AUTOSAR XML (schema 4-0-3)
package /ComponentType
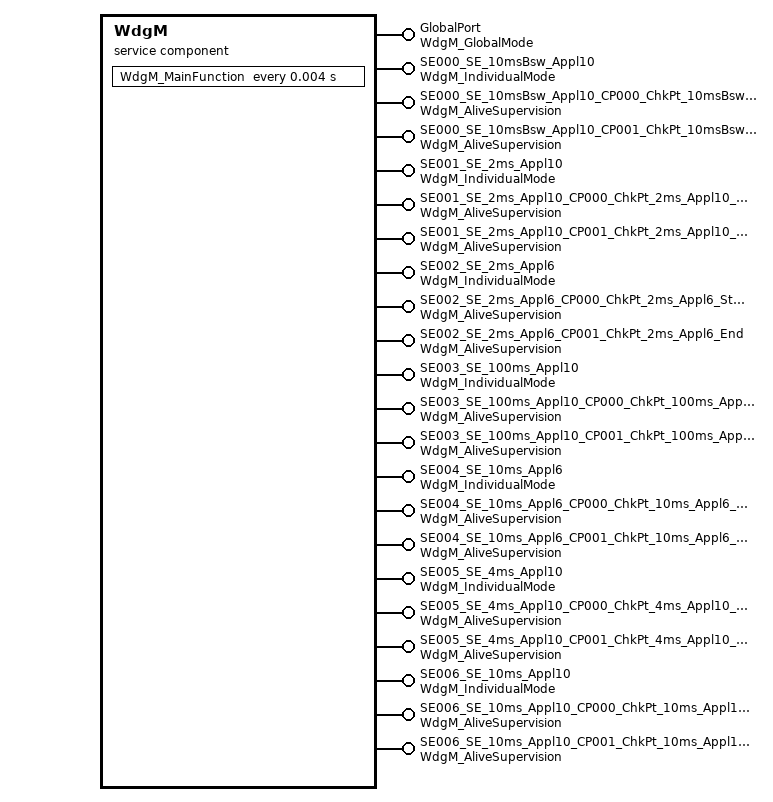
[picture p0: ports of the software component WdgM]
  service sw component type WdgM
    22 x provide port:
      GlobalPort: provided-interface=WdgM_GlobalMode  # P-Port Prototype for Global Mode
        provided-com-specs:
          operation=GetGlobalStatus, queue-length=1
          operation=GetMode, queue-length=1
          operation=PerformReset, queue-length=1
      SE000_SE_10msBsw_Appl10: provided-interface=WdgM_IndividualMode  # P-Port Prototype for Supervised Entity SE_10msBsw_Appl10 with ID 0
        provided-com-specs:
          operation=ActivateSupervisionEntity, queue-length=1
          operation=DeactivateSupervisionEntity, queue-length=1
          operation=GetLocalStatus, queue-length=1
      SE000_SE_10msBsw_Appl10_CP000_ChkPt_10msBsw_Appl10_Strt: server-com-spec{operation=CheckpointReached, queue-length=1}, provided-interface=WdgM_AliveSupervision  # P-Port Prototype for Supervised Entity SE_10msBsw_Appl10 with ID 0 and Checkpoint ChkPt_10msBsw_Appl10_Strt with ID 0.
      SE000_SE_10msBsw_Appl10_CP001_ChkPt_10msBsw_Appl10_End: server-com-spec{operation=CheckpointReached, queue-length=1}, provided-interface=WdgM_AliveSupervision  # P-Port Prototype for Supervised Entity SE_10msBsw_Appl10 with ID 0 and Checkpoint ChkPt_10msBsw_Appl10_End with ID 1.
      SE001_SE_2ms_Appl10: provided-interface=WdgM_IndividualMode  # P-Port Prototype for Supervised Entity SE_2ms_Appl10 with ID 1
        provided-com-specs:
          operation=ActivateSupervisionEntity, queue-length=1
          operation=DeactivateSupervisionEntity, queue-length=1
          operation=GetLocalStatus, queue-length=1
      SE001_SE_2ms_Appl10_CP000_ChkPt_2ms_Appl10_Strt: server-com-spec{operation=CheckpointReached, queue-length=1}, provided-interface=WdgM_AliveSupervision  # P-Port Prototype for Supervised Entity SE_2ms_Appl10 with ID 1 and Checkpoint ChkPt_2ms_Appl10_Strt with ID 0.
      SE001_SE_2ms_Appl10_CP001_ChkPt_2ms_Appl10_End: server-com-spec{operation=CheckpointReached, queue-length=1}, provided-interface=WdgM_AliveSupervision  # P-Port Prototype for Supervised Entity SE_2ms_Appl10 with ID 1 and Checkpoint ChkPt_2ms_Appl10_End with ID 1.
      SE002_SE_2ms_Appl6: provided-interface=WdgM_IndividualMode  # P-Port Prototype for Supervised Entity SE_2ms_Appl6 with ID 2
        provided-com-specs:
          operation=ActivateSupervisionEntity, queue-length=1
          operation=DeactivateSupervisionEntity, queue-length=1
          operation=GetLocalStatus, queue-length=1
      SE002_SE_2ms_Appl6_CP000_ChkPt_2ms_Appl6_Strt: server-com-spec{operation=CheckpointReached, queue-length=1}, provided-interface=WdgM_AliveSupervision  # P-Port Prototype for Supervised Entity SE_2ms_Appl6 with ID 2 and Checkpoint ChkPt_2ms_Appl6_Strt with ID 0.
      SE002_SE_2ms_Appl6_CP001_ChkPt_2ms_Appl6_End: server-com-spec{operation=CheckpointReached, queue-length=1}, provided-interface=WdgM_AliveSupervision  # P-Port Prototype for Supervised Entity SE_2ms_Appl6 with ID 2 and Checkpoint ChkPt_2ms_Appl6_End with ID 1.
      SE003_SE_100ms_Appl10: provided-interface=WdgM_IndividualMode  # P-Port Prototype for Supervised Entity SE_100ms_Appl10 with ID 3
        provided-com-specs:
          operation=ActivateSupervisionEntity, queue-length=1
          operation=DeactivateSupervisionEntity, queue-length=1
          operation=GetLocalStatus, queue-length=1
      SE003_SE_100ms_Appl10_CP000_ChkPt_100ms_Appl10_Strt: server-com-spec{operation=CheckpointReached, queue-length=1}, provided-interface=WdgM_AliveSupervision  # P-Port Prototype for Supervised Entity SE_100ms_Appl10 with ID 3 and Checkpoint ChkPt_100ms_Appl10_Strt with ID 0.
      SE003_SE_100ms_Appl10_CP001_ChkPt_100ms_Appl10_End: server-com-spec{operation=CheckpointReached, queue-length=1}, provided-interface=WdgM_AliveSupervision  # P-Port Prototype for Supervised Entity SE_100ms_Appl10 with ID 3 and Checkpoint ChkPt_100ms_Appl10_End with ID 1.
      SE004_SE_10ms_Appl6: provided-interface=WdgM_IndividualMode  # P-Port Prototype for Supervised Entity SE_10ms_Appl6 with ID 4
        provided-com-specs:
          operation=ActivateSupervisionEntity, queue-length=1
          operation=DeactivateSupervisionEntity, queue-length=1
          operation=GetLocalStatus, queue-length=1
      SE004_SE_10ms_Appl6_CP000_ChkPt_10ms_Appl6_Strt: server-com-spec{operation=CheckpointReached, queue-length=1}, provided-interface=WdgM_AliveSupervision  # P-Port Prototype for Supervised Entity SE_10ms_Appl6 with ID 4 and Checkpoint ChkPt_10ms_Appl6_Strt with ID 0.
      SE004_SE_10ms_Appl6_CP001_ChkPt_10ms_Appl6_End: server-com-spec{operation=CheckpointReached, queue-length=1}, provided-interface=WdgM_AliveSupervision  # P-Port Prototype for Supervised Entity SE_10ms_Appl6 with ID 4 and Checkpoint ChkPt_10ms_Appl6_End with ID 1.
      SE005_SE_4ms_Appl10: provided-interface=WdgM_IndividualMode  # P-Port Prototype for Supervised Entity SE_4ms_Appl10 with ID 5
        provided-com-specs:
          operation=ActivateSupervisionEntity, queue-length=1
          operation=DeactivateSupervisionEntity, queue-length=1
          operation=GetLocalStatus, queue-length=1
      SE005_SE_4ms_Appl10_CP000_ChkPt_4ms_Appl10_Strt: server-com-spec{operation=CheckpointReached, queue-length=1}, provided-interface=WdgM_AliveSupervision  # P-Port Prototype for Supervised Entity SE_4ms_Appl10 with ID 5 and Checkpoint ChkPt_4ms_Appl10_Strt with ID 0.
      SE005_SE_4ms_Appl10_CP001_ChkPt_4ms_Appl10_End: server-com-spec{operation=CheckpointReached, queue-length=1}, provided-interface=WdgM_AliveSupervision  # P-Port Prototype for Supervised Entity SE_4ms_Appl10 with ID 5 and Checkpoint ChkPt_4ms_Appl10_End with ID 1.
      SE006_SE_10ms_Appl10: provided-interface=WdgM_IndividualMode  # P-Port Prototype for Supervised Entity SE_10ms_Appl10 with ID 6
        provided-com-specs:
          operation=ActivateSupervisionEntity, queue-length=1
          operation=DeactivateSupervisionEntity, queue-length=1
          operation=GetLocalStatus, queue-length=1
      SE006_SE_10ms_Appl10_CP000_ChkPt_10ms_Appl10_Strt: server-com-spec{operation=CheckpointReached, queue-length=1}, provided-interface=WdgM_AliveSupervision  # P-Port Prototype for Supervised Entity SE_10ms_Appl10 with ID 6 and Checkpoint ChkPt_10ms_Appl10_Strt with ID 0.
      SE006_SE_10ms_Appl10_CP001_ChkPt_10ms_Appl10_End: server-com-spec{operation=CheckpointReached, queue-length=1}, provided-interface=WdgM_AliveSupervision  # P-Port Prototype for Supervised Entity SE_10ms_Appl10 with ID 6 and Checkpoint ChkPt_10ms_Appl10_End with ID 1.
    behavior WdgM_InternalBehavior
      38 x operation invoked event:
        V_WDGM_SE000_SE_10msBsw_Appl10_ASE: start-on-event=ActivateSupervisionEntity, operation=SE000_SE_10msBsw_Appl10.ActivateSupervisionEntity
        V_WDGM_SE001_SE_2ms_Appl10_ASE: start-on-event=ActivateSupervisionEntity, operation=SE001_SE_2ms_Appl10.ActivateSupervisionEntity
        V_WDGM_SE002_SE_2ms_Appl6_ASE: start-on-event=ActivateSupervisionEntity, operation=SE002_SE_2ms_Appl6.ActivateSupervisionEntity
        V_WDGM_SE003_SE_100ms_Appl10_ASE: start-on-event=ActivateSupervisionEntity, operation=SE003_SE_100ms_Appl10.ActivateSupervisionEntity
        V_WDGM_SE004_SE_10ms_Appl6_ASE: start-on-event=ActivateSupervisionEntity, operation=SE004_SE_10ms_Appl6.ActivateSupervisionEntity
        V_WDGM_SE005_SE_4ms_Appl10_ASE: start-on-event=ActivateSupervisionEntity, operation=SE005_SE_4ms_Appl10.ActivateSupervisionEntity
        V_WDGM_SE006_SE_10ms_Appl10_ASE: start-on-event=ActivateSupervisionEntity, operation=SE006_SE_10ms_Appl10.ActivateSupervisionEntity
        V_WDGM_SE000_SE_10msBsw_Appl10_CP000_ChkPt_10msBsw_Appl10_Strt_CPR: start-on-event=CheckpointReached, operation=SE000_SE_10msBsw_Appl10_CP000_ChkPt_10msBsw_Appl10_Strt.CheckpointReached
        V_WDGM_SE000_SE_10msBsw_Appl10_CP001_ChkPt_10msBsw_Appl10_End_CPR: start-on-event=CheckpointReached, operation=SE000_SE_10msBsw_Appl10_CP001_ChkPt_10msBsw_Appl10_End.CheckpointReached
        V_WDGM_SE001_SE_2ms_Appl10_CP000_ChkPt_2ms_Appl10_Strt_CPR: start-on-event=CheckpointReached, operation=SE001_SE_2ms_Appl10_CP000_ChkPt_2ms_Appl10_Strt.CheckpointReached
        V_WDGM_SE001_SE_2ms_Appl10_CP001_ChkPt_2ms_Appl10_End_CPR: start-on-event=CheckpointReached, operation=SE001_SE_2ms_Appl10_CP001_ChkPt_2ms_Appl10_End.CheckpointReached
        V_WDGM_SE002_SE_2ms_Appl6_CP000_ChkPt_2ms_Appl6_Strt_CPR: start-on-event=CheckpointReached, operation=SE002_SE_2ms_Appl6_CP000_ChkPt_2ms_Appl6_Strt.CheckpointReached
        V_WDGM_SE002_SE_2ms_Appl6_CP001_ChkPt_2ms_Appl6_End_CPR: start-on-event=CheckpointReached, operation=SE002_SE_2ms_Appl6_CP001_ChkPt_2ms_Appl6_End.CheckpointReached
        V_WDGM_SE003_SE_100ms_Appl10_CP000_ChkPt_100ms_Appl10_Strt_CPR: start-on-event=CheckpointReached, operation=SE003_SE_100ms_Appl10_CP000_ChkPt_100ms_Appl10_Strt.CheckpointReached
        V_WDGM_SE003_SE_100ms_Appl10_CP001_ChkPt_100ms_Appl10_End_CPR: start-on-event=CheckpointReached, operation=SE003_SE_100ms_Appl10_CP001_ChkPt_100ms_Appl10_End.CheckpointReached
        V_WDGM_SE004_SE_10ms_Appl6_CP000_ChkPt_10ms_Appl6_Strt_CPR: start-on-event=CheckpointReached, operation=SE004_SE_10ms_Appl6_CP000_ChkPt_10ms_Appl6_Strt.CheckpointReached
        V_WDGM_SE004_SE_10ms_Appl6_CP001_ChkPt_10ms_Appl6_End_CPR: start-on-event=CheckpointReached, operation=SE004_SE_10ms_Appl6_CP001_ChkPt_10ms_Appl6_End.CheckpointReached
        V_WDGM_SE005_SE_4ms_Appl10_CP000_ChkPt_4ms_Appl10_Strt_CPR: start-on-event=CheckpointReached, operation=SE005_SE_4ms_Appl10_CP000_ChkPt_4ms_Appl10_Strt.CheckpointReached
        V_WDGM_SE005_SE_4ms_Appl10_CP001_ChkPt_4ms_Appl10_End_CPR: start-on-event=CheckpointReached, operation=SE005_SE_4ms_Appl10_CP001_ChkPt_4ms_Appl10_End.CheckpointReached
        V_WDGM_SE006_SE_10ms_Appl10_CP000_ChkPt_10ms_Appl10_Strt_CPR: start-on-event=CheckpointReached, operation=SE006_SE_10ms_Appl10_CP000_ChkPt_10ms_Appl10_Strt.CheckpointReached
        V_WDGM_SE006_SE_10ms_Appl10_CP001_ChkPt_10ms_Appl10_End_CPR: start-on-event=CheckpointReached, operation=SE006_SE_10ms_Appl10_CP001_ChkPt_10ms_Appl10_End.CheckpointReached
        V_WDGM_SE000_SE_10msBsw_Appl10_DSE: start-on-event=DeactivateSupervisionEntity, operation=SE000_SE_10msBsw_Appl10.DeactivateSupervisionEntity
        V_WDGM_SE001_SE_2ms_Appl10_DSE: start-on-event=DeactivateSupervisionEntity, operation=SE001_SE_2ms_Appl10.DeactivateSupervisionEntity
        V_WDGM_SE002_SE_2ms_Appl6_DSE: start-on-event=DeactivateSupervisionEntity, operation=SE002_SE_2ms_Appl6.DeactivateSupervisionEntity
        V_WDGM_SE003_SE_100ms_Appl10_DSE: start-on-event=DeactivateSupervisionEntity, operation=SE003_SE_100ms_Appl10.DeactivateSupervisionEntity
        V_WDGM_SE004_SE_10ms_Appl6_DSE: start-on-event=DeactivateSupervisionEntity, operation=SE004_SE_10ms_Appl6.DeactivateSupervisionEntity
        V_WDGM_SE005_SE_4ms_Appl10_DSE: start-on-event=DeactivateSupervisionEntity, operation=SE005_SE_4ms_Appl10.DeactivateSupervisionEntity
        V_WDGM_SE006_SE_10ms_Appl10_DSE: start-on-event=DeactivateSupervisionEntity, operation=SE006_SE_10ms_Appl10.DeactivateSupervisionEntity
        V_WDGM_GGS: start-on-event=GetGlobalStatus, operation=GlobalPort.GetGlobalStatus
        V_WDGM_SE000_SE_10msBsw_Appl10_GLS: start-on-event=GetLocalStatus, operation=SE000_SE_10msBsw_Appl10.GetLocalStatus
        V_WDGM_SE001_SE_2ms_Appl10_GLS: start-on-event=GetLocalStatus, operation=SE001_SE_2ms_Appl10.GetLocalStatus
        V_WDGM_SE002_SE_2ms_Appl6_GLS: start-on-event=GetLocalStatus, operation=SE002_SE_2ms_Appl6.GetLocalStatus
        V_WDGM_SE003_SE_100ms_Appl10_GLS: start-on-event=GetLocalStatus, operation=SE003_SE_100ms_Appl10.GetLocalStatus
        V_WDGM_SE004_SE_10ms_Appl6_GLS: start-on-event=GetLocalStatus, operation=SE004_SE_10ms_Appl6.GetLocalStatus
        V_WDGM_SE005_SE_4ms_Appl10_GLS: start-on-event=GetLocalStatus, operation=SE005_SE_4ms_Appl10.GetLocalStatus
        V_WDGM_SE006_SE_10ms_Appl10_GLS: start-on-event=GetLocalStatus, operation=SE006_SE_10ms_Appl10.GetLocalStatus
        V_WDGM_GMO: start-on-event=GetMode, operation=GlobalPort.GetMode
        V_WDGM_PRE: start-on-event=PerformReset, operation=GlobalPort.PerformReset
      timing event V_WDGM_MAI: start-on-event=WdgM_MainFunction, period=0.004
      port-api-options:
        {enable-take-address=false, indirect-api=false, port-defined-argument-value{value=SE000_SE_10msBsw_Appl10_0:0, value-type=WdgM_SupervisedEntityIdType}, port=SE000_SE_10msBsw_Appl10}
        {enable-take-address=false, indirect-api=false, port-arg-values=[{value=SE000_SE_10msBsw_Appl10_CP000_ChkPt_10msBsw_Appl10_Strt_0:0, value-type=WdgM_SupervisedEntityIdType}, {value=SE000_SE_10msBsw_Appl10_CP000_ChkPt_10msBsw_Appl10_Strt_1:0, value-type=WdgM_CheckpointIdType}], port=SE000_SE_10msBsw_Appl10_CP000_ChkPt_10msBsw_Appl10_Strt}
        {enable-take-address=false, indirect-api=false, port-arg-values=[{value=SE000_SE_10msBsw_Appl10_CP001_ChkPt_10msBsw_Appl10_End_0:0, value-type=WdgM_SupervisedEntityIdType}, {value=SE000_SE_10msBsw_Appl10_CP001_ChkPt_10msBsw_Appl10_End_1:1, value-type=WdgM_CheckpointIdType}], port=SE000_SE_10msBsw_Appl10_CP001_ChkPt_10msBsw_Appl10_End}
        {enable-take-address=false, indirect-api=false, port-defined-argument-value{value=SE001_SE_2ms_Appl10_0:1, value-type=WdgM_SupervisedEntityIdType}, port=SE001_SE_2ms_Appl10}
        {enable-take-address=false, indirect-api=false, port-arg-values=[{value=SE001_SE_2ms_Appl10_CP000_ChkPt_2ms_Appl10_Strt_0:1, value-type=WdgM_SupervisedEntityIdType}, {value=SE001_SE_2ms_Appl10_CP000_ChkPt_2ms_Appl10_Strt_1:0, value-type=WdgM_CheckpointIdType}], port=SE001_SE_2ms_Appl10_CP000_ChkPt_2ms_Appl10_Strt}
        {enable-take-address=false, indirect-api=false, port-arg-values=[{value=SE001_SE_2ms_Appl10_CP001_ChkPt_2ms_Appl10_End_0:1, value-type=WdgM_SupervisedEntityIdType}, {value=SE001_SE_2ms_Appl10_CP001_ChkPt_2ms_Appl10_End_1:1, value-type=WdgM_CheckpointIdType}], port=SE001_SE_2ms_Appl10_CP001_ChkPt_2ms_Appl10_End}
        {enable-take-address=false, indirect-api=false, port-defined-argument-value{value=SE002_SE_2ms_Appl6_0:2, value-type=WdgM_SupervisedEntityIdType}, port=SE002_SE_2ms_Appl6}
        {enable-take-address=false, indirect-api=false, port-arg-values=[{value=SE002_SE_2ms_Appl6_CP000_ChkPt_2ms_Appl6_Strt_0:2, value-type=WdgM_SupervisedEntityIdType}, {value=SE002_SE_2ms_Appl6_CP000_ChkPt_2ms_Appl6_Strt_1:0, value-type=WdgM_CheckpointIdType}], port=SE002_SE_2ms_Appl6_CP000_ChkPt_2ms_Appl6_Strt}
        {enable-take-address=false, indirect-api=false, port-arg-values=[{value=SE002_SE_2ms_Appl6_CP001_ChkPt_2ms_Appl6_End_0:2, value-type=WdgM_SupervisedEntityIdType}, {value=SE002_SE_2ms_Appl6_CP001_ChkPt_2ms_Appl6_End_1:1, value-type=WdgM_CheckpointIdType}], port=SE002_SE_2ms_Appl6_CP001_ChkPt_2ms_Appl6_End}
        {enable-take-address=false, indirect-api=false, port-defined-argument-value{value=SE003_SE_100ms_Appl10_0:3, value-type=WdgM_SupervisedEntityIdType}, port=SE003_SE_100ms_Appl10}
        {enable-take-address=false, indirect-api=false, port-arg-values=[{value=SE003_SE_100ms_Appl10_CP000_ChkPt_100ms_Appl10_Strt_0:3, value-type=WdgM_SupervisedEntityIdType}, {value=SE003_SE_100ms_Appl10_CP000_ChkPt_100ms_Appl10_Strt_1:0, value-type=WdgM_CheckpointIdType}], port=SE003_SE_100ms_Appl10_CP000_ChkPt_100ms_Appl10_Strt}
        {enable-take-address=false, indirect-api=false, port-arg-values=[{value=SE003_SE_100ms_Appl10_CP001_ChkPt_100ms_Appl10_End_0:3, value-type=WdgM_SupervisedEntityIdType}, {value=SE003_SE_100ms_Appl10_CP001_ChkPt_100ms_Appl10_End_1:1, value-type=WdgM_CheckpointIdType}], port=SE003_SE_100ms_Appl10_CP001_ChkPt_100ms_Appl10_End}
        {enable-take-address=false, indirect-api=false, port-defined-argument-value{value=SE004_SE_10ms_Appl6_0:4, value-type=WdgM_SupervisedEntityIdType}, port=SE004_SE_10ms_Appl6}
        {enable-take-address=false, indirect-api=false, port-arg-values=[{value=SE004_SE_10ms_Appl6_CP000_ChkPt_10ms_Appl6_Strt_0:4, value-type=WdgM_SupervisedEntityIdType}, {value=SE004_SE_10ms_Appl6_CP000_ChkPt_10ms_Appl6_Strt_1:0, value-type=WdgM_CheckpointIdType}], port=SE004_SE_10ms_Appl6_CP000_ChkPt_10ms_Appl6_Strt}
        {enable-take-address=false, indirect-api=false, port-arg-values=[{value=SE004_SE_10ms_Appl6_CP001_ChkPt_10ms_Appl6_End_0:4, value-type=WdgM_SupervisedEntityIdType}, {value=SE004_SE_10ms_Appl6_CP001_ChkPt_10ms_Appl6_End_1:1, value-type=WdgM_CheckpointIdType}], port=SE004_SE_10ms_Appl6_CP001_ChkPt_10ms_Appl6_End}
        {enable-take-address=false, indirect-api=false, port-defined-argument-value{value=SE005_SE_4ms_Appl10_0:5, value-type=WdgM_SupervisedEntityIdType}, port=SE005_SE_4ms_Appl10}
        {enable-take-address=false, indirect-api=false, port-arg-values=[{value=SE005_SE_4ms_Appl10_CP000_ChkPt_4ms_Appl10_Strt_0:5, value-type=WdgM_SupervisedEntityIdType}, {value=SE005_SE_4ms_Appl10_CP000_ChkPt_4ms_Appl10_Strt_1:0, value-type=WdgM_CheckpointIdType}], port=SE005_SE_4ms_Appl10_CP000_ChkPt_4ms_Appl10_Strt}
        {enable-take-address=false, indirect-api=false, port-arg-values=[{value=SE005_SE_4ms_Appl10_CP001_ChkPt_4ms_Appl10_End_0:5, value-type=WdgM_SupervisedEntityIdType}, {value=SE005_SE_4ms_Appl10_CP001_ChkPt_4ms_Appl10_End_1:1, value-type=WdgM_CheckpointIdType}], port=SE005_SE_4ms_Appl10_CP001_ChkPt_4ms_Appl10_End}
        {enable-take-address=false, indirect-api=false, port-defined-argument-value{value=SE006_SE_10ms_Appl10_0:6, value-type=WdgM_SupervisedEntityIdType}, port=SE006_SE_10ms_Appl10}
        {enable-take-address=false, indirect-api=false, port-arg-values=[{value=SE006_SE_10ms_Appl10_CP000_ChkPt_10ms_Appl10_Strt_0:6, value-type=WdgM_SupervisedEntityIdType}, {value=SE006_SE_10ms_Appl10_CP000_ChkPt_10ms_Appl10_Strt_1:0, value-type=WdgM_CheckpointIdType}], port=SE006_SE_10ms_Appl10_CP000_ChkPt_10ms_Appl10_Strt}
        {enable-take-address=false, indirect-api=false, port-arg-values=[{value=SE006_SE_10ms_Appl10_CP001_ChkPt_10ms_Appl10_End_0:6, value-type=WdgM_SupervisedEntityIdType}, {value=SE006_SE_10ms_Appl10_CP001_ChkPt_10ms_Appl10_End_1:1, value-type=WdgM_CheckpointIdType}], port=SE006_SE_10ms_Appl10_CP001_ChkPt_10ms_Appl10_End}
      8 x runnable, all with can-be-invoked-concurrently=true:
        ActivateSupervisionEntity: symbol=WdgM_ActivateSupervisionEntity
        CheckpointReached: symbol=WdgM_CheckpointReached
        DeactivateSupervisionEntity: symbol=WdgM_DeactivateSupervisionEntity
        GetGlobalStatus: symbol=WdgM_GetGlobalStatus
        GetLocalStatus: symbol=WdgM_GetLocalStatus
        GetMode: symbol=WdgM_GetMode
        PerformReset: symbol=WdgM_PerformReset
        WdgM_MainFunction
  swc implementation WdgM_Implementation: behavior=WdgM_InternalBehavior
    code-descriptors:
      code Default: artifact-descriptors=autosar-engineering-object={short-label=Default, category=SWSRC}
